# TC37XPD register map
Vendor: Infineon; Series: ATVMC; File version: 100
CPU: other r0p0, little endian, MPU, FPU, vendor SysTick, 4 interrupt priority bits
Registers are 32-bit, read-write, reset 0x0 unless marked. A register's access mark holds for its fields unless they carry their own. Offsets are from the block's base; [hi:lo] are bit positions; {n}, {i} and the like mark numbered series.

## GPT120 — GPT12
Base 0xF0001800
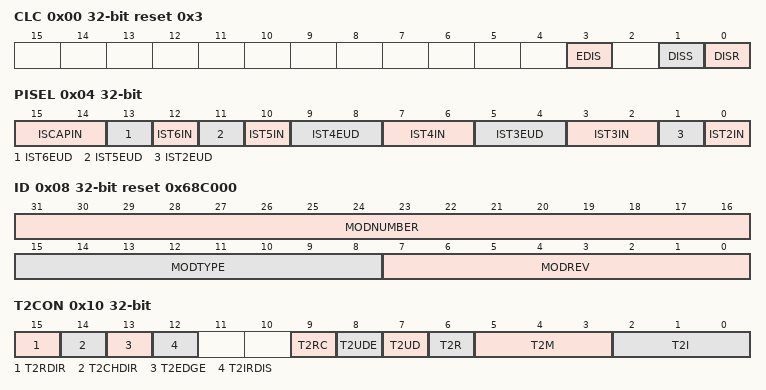
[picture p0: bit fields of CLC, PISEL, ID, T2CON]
0x00 CLC access per field reset 0x3 — Clock Control Register resetvalue={Application Reset:0x3}
  [3] EDIS rw — Sleep Mode Enable Control EDIS. Used to control module 8217 s sleep mode.
  [1] DISS ro — Module Disable Status Bit DISS. Bit indicates the current status of the module.
  [0] DISR rw — Module Disable Request Bit DISR. Used for enable disable control of the module.
0x04 PISEL — Port Input Select Register resetvalue={Application Reset:0x0}
  [15:14] ISCAPIN — Input Select for CAPIN ISCAPIN
  [13] IST6EUD — Input Select for T6EUD IST6EUD
  [12] IST6IN — Input Select for T6IN IST6IN
  [11] IST5EUD — Input Select for T5EUD IST5EUD
  [10] IST5IN — Input Select for T5IN IST5IN
  [9:8] IST4EUD — Input Select for T4EUD IST4EUD
  [7:6] IST4IN — Input Select for T4IN IST4IN
  [5:4] IST3EUD — Input Select for T3EUD IST3EUD
  [3:2] IST3IN — Input Select for T3IN IST3IN
  [1] IST2EUD — Input Select for T2EUD IST2EUD
  [0] IST2IN — Input Select for T2IN IST2IN
0x08 ID ro reset 0x68C000 (reset mask 0xFFFFFF00) — Identification Register resetvalue={Application Reset:0x68C000,Application Reset:0x68C001}
  [31:16] MODNUMBER — Module Number MODNUMBER. This bit field defines the module identification number. For the GPT12 module the module identification number is 68 H .
  [15:8] MODTYPE — Module Type MODTYPE. This bit field is C0 H . It defines a 32 bit module
  [7:0] MODREV — Module Revision Number MODREV. This bit field indicates the revision number of the module 01 H 160 160 first revision .
0x10 T2CON access per field — Timer T2 Control Register resetvalue={Application Reset:0x0}
  [15] T2RDIR ro — Timer T2 Rotation Direction T2RDIR
  [14] T2CHDIR rw — Timer T2 Count Direction Change T2CHDIR. The bit is set each time the count direction of timer T2 changes. T2CHDIR must be cleared by software.
  [13] T2EDGE rw — Timer T2 Edge Detection T2EDGE. The bit is set each time a count edge is detected. T2EDGE must be cleared by software.
  [12] T2IRDIS rw — Timer T2 Interrupt Disable T2IRDIS
  [9] T2RC rw — Timer T2 Remote Control T2RC
  [8] T2UDE rw — Timer T2 External Up Down Enable T2UDE
  [7] T2UD rw — Timer T2 Up Down Control T2UD. This bit only directly controls count direction of T2 if bit T2UDE 0.
  [6] T2R rw — Timer T2 Run Bit T2R. This bit only controls timer T2 if bit T2RC 0.
  [5:3] T2M rw — Timer T2 Mode Control Basic Operating Mode T2M
  [2:0] T2I rw — Timer T2 Input Parameter Selection T2I. Depends on the operating mode see respective sections for encoding CROSSREFERENCE for Timer Mode and Gated Timer Mode CROSSREFERENCE for Counter Mode CROSSREFERENCE for Incremental Interface Mode
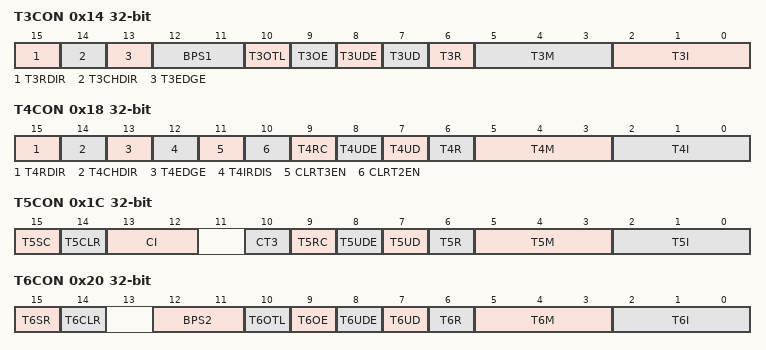
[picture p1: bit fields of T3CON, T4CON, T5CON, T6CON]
0x14 T3CON access per field — Timer T3 Control Register resetvalue={Application Reset:0x0}
  [15] T3RDIR ro — Timer T3 Rotation Direction Flag T3RDIR
  [14] T3CHDIR rw — Timer T3 Count Direction Change Flag T3CHDIR. This bit is set each time the count direction of timer T3 changes. T3CHDIR must be cleared by software.
  [13] T3EDGE rw — Timer T3 Edge Detection Flag T3EDGE. The bit is set each time a count edge is detected. T3EDGE must be cleared by software.
  [12:11] BPS1 rw — GPT1 Block Prescaler Control BPS1. Selects the basic clock for block GPT1 see also CROSSREFERENCE
  [10] T3OTL rw — Timer T3 Overflow Toggle Latch T3OTL. Toggles on each overflow underflow of T3. Can be set or cleared by software see separate description
  [9] T3OE rw — Overflow Underflow Output Enable T3OE
  [8] T3UDE rw — Timer T3 External Up Down Enable T3UDE
  [7] T3UD rw — Timer T3 Up Down Control T3UD. This bit only directly controls count direction of T3 if bit T3UDE 0.
  [6] T3R rw — Timer T3 Run Bit T3R
  [5:3] T3M rw — Timer T3 Mode Control T3M
  [2:0] T3I rw — Timer T3 Input Parameter Selection T3I. Depends on the operating mode see respective sections for encoding CROSSREFERENCE for Timer Mode and Gated Timer Mode CROSSREFERENCE for Counter Mode CROSSREFERENCE for Incremental Interface Mode
0x18 T4CON access per field — Timer T4 Control Register resetvalue={Application Reset:0x0}
  [15] T4RDIR ro — Timer T4 Rotation Direction T4RDIR
  [14] T4CHDIR rw — Timer T4 Count Direction Change T4CHDIR. The bit is set each time the count direction of timer T4 changes. T4CHDIR must be cleared by software.
  [13] T4EDGE rw — Timer T4 Edge Detection T4EDGE. The bit is set each time a count edge is detected. T4EDGE has to be cleared by software.
  [12] T4IRDIS rw — Timer T4 Interrupt Disable T4IRDIS
  [11] CLRT3EN rw — Clear Timer T3 Enable CLRT3EN. Enables the automatic clearing of timer T3 upon a falling edge of the selected T4IN input.
  [10] CLRT2EN rw — Clear Timer T2 Enable CLRT2EN. Enables the automatic clearing of timer T2 upon a falling edge of the selected T4EUD input.
  [9] T4RC rw — Timer T4 Remote Control T4RC
  [8] T4UDE rw — Timer T4 External Up Down Enable T4UDE
  [7] T4UD rw — Timer T4 Up Down Control T4UD. This bit only directly controls count direction of T4 if bit T4UDE 0.
  [6] T4R rw — Timer T4 Run Bit T4R. This bit only controls timer T4 if bit T4RC 0.
  [5:3] T4M rw — Timer T4 Mode Control Basic Operating Mode T4M
  [2:0] T4I rw — Timer T4 Input Parameter Selection T4I. Depends on the operating mode see respective sections for encoding CROSSREFERENCE for Timer Mode and Gated Timer Mode CROSSREFERENCE for Counter Mode CROSSREFERENCE for Incremental Interface Mode
0x1C T5CON — Timer T5 Control Register resetvalue={Application Reset:0x0}
  [15] T5SC — Timer T5 Capture Mode Enable T5SC
  [14] T5CLR — Timer T5 Clear Enable Bit T5CLR
  [13:12] CI — Register CAPREL Capture Trigger Selection CI
  [10] CT3 — Timer T3 Capture Trigger Enable CT3
  [9] T5RC — Timer T5 Remote Control T5RC
  [8] T5UDE — Timer T5 External Up Down Enable T5UDE
  [7] T5UD — Timer T5 Up Down Control T5UD. This bit only directly controls count direction of T5 if bit T5UDE 0.
  [6] T5R — Timer T5 Run Bit T5R. This bit only controls timer T5 if bit T5RC 0.
  [5:3] T5M — Timer T5 Mode Control Basic Operating Mode T5M. In the implementation the T5M bit field has only 2 bits and T5CON bit 5 is reserved AI00045855 .
  [2:0] T5I — Timer T5 Input Parameter Selection T5I. Depends on the operating mode see respective sections for encoding CROSSREFERENCE for Timer Mode and Gated Timer Mode CROSSREFERENCE for Counter Mode
0x20 T6CON — Timer T6 Control Register resetvalue={Application Reset:0x0}
  [15] T6SR — Timer T6 Reload Mode Enable T6SR
  [14] T6CLR — Timer T6 Clear Enable Bit T6CLR
  [12:11] BPS2 — GPT2 Block Prescaler Control BPS2. Selects the basic clock for block GPT2 see also CROSSREFERENCE
  [10] T6OTL — Timer T6 Overflow Toggle Latch T6OTL. Toggles on each overflow underflow of timer T6. Can be set or cleared by software see separate description
  [9] T6OE — Overflow Underflow Output Enable T6OE
  [8] T6UDE — Timer T6 External Up Down Enable T6UDE
  [7] T6UD — Timer T6 Up Down Control T6UD. This bit only directly controls count direction of T6 if bit T6UDE 0.
  [6] T6R — Timer T6 Run Bit T6R
  [5:3] T6M — Timer T6 Mode Control Basic Operating Mode T6M
  [2:0] T6I — Timer T6 Input Parameter Selection T6I. Depends on the operating mode see respective sections for encoding CROSSREFERENCE for Timer Mode and Gated Timer Mode CROSSREFERENCE for Counter Mode
0x30 CAPREL — Capture and Reload Register resetvalue={Application Reset:0x0}
  [15:0] CAPREL — Current reload value or Captured value CAPREL
0x34 T2 — Timer T2 Register resetvalue={Application Reset:0x0}
  [15:0] T2 — Timer T2 T2. Contains the current value of Timer T2.
0x38 T3 — Timer T3 Register resetvalue={Application Reset:0x0}
  [15:0] T3 — Timer T3 T3. Contains the current value of Timer T3.
0x3C T4 — Timer T4 Register resetvalue={Application Reset:0x0}
  [15:0] T4 — Timer T4 T4. Contains the current value of Timer T4.
0x40 T5 — Timer T5 Register resetvalue={Application Reset:0x0}
  [15:0] T5 — Timer T5 T5. Contains the current value of Timer T5.
0x44 T6 — Timer T6 Register resetvalue={Application Reset:0x0}
  [15:0] T6 — Timer T6 T6. Contains the current value of Timer T6.
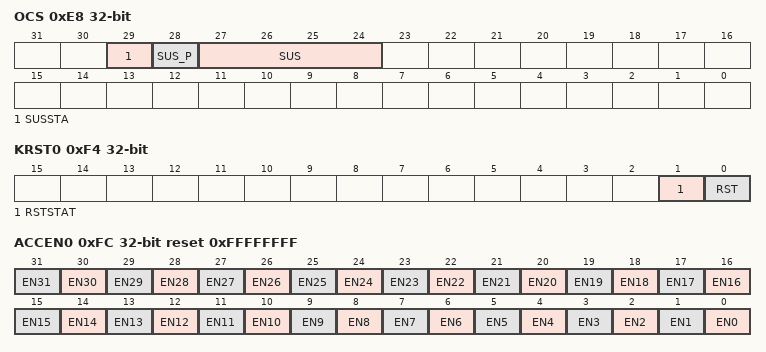
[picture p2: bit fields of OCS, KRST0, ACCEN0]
0xE8 OCS access per field — OCDS Control and Status Register resetvalue={PowerOn Reset:0x0,Debug Reset:0x0}
  [29] SUSSTA ro — Suspend State SUSSTA
  [28] SUS_P wo — SUS Write Protection SUS P. SUS is only written when SUS P is 1 otherwise unchanged. Read as 0.
  [27:24] SUS rw — OCDS Suspend Control SUS. Controls the sensitivity to the suspend signal coming from the OCDS Trigger Switch OTGS
0xEC KRSTCLR wo — Kernel Reset Status Clear Register resetvalue={Application Reset:0x0}
  [0] CLR — Kernel Reset Status Clear CLR. Read always as 0.
0xF0 KRST1 — Kernel Reset Register 1 resetvalue={Application Reset:0x0}
  [0] RST — Kernel Reset RST. This reset bit can be used to request for a kernel reset. The kernel reset will be executed if the reset bits of both kernel reset registers is set. The RST bit will be cleared re set to 0 by the BPI after the kernel reset was executed.
0xF4 KRST0 access per field — Kernel Reset Register 0 resetvalue={Application Reset:0x0}
  [1] RSTSTAT ro — Kernel Reset Status RSTSTAT. This bit indicates wether a kernel reset was executed or not. This bit is set after the execution of a kernel reset in the same clock cycle in which the reset bits are cleared. This bit can be cleared by writing with 180 1 180 to the CLR bit in the related KRSTCLR register.
  [0] RST rw — Kernel Reset RST. This reset bit can be used to request for a kernel reset. The kernel reset will be executed if the reset bits of both kernel registers are set. The RST bit will be cleared re set to 180 0 180 by the BPI after the kernel reset was executed.
0xFC ACCEN0 reset 0xFFFFFFFF — Access Enable Register 0 resetvalue={Application Reset:0x0FFFFFFFF}
  [n] EN{n} (n=0..31) — Access Enable for Master TAG ID 31 EN31. This bit enables write access to the module kernel addresses for transactions with the Master TAG ID y
